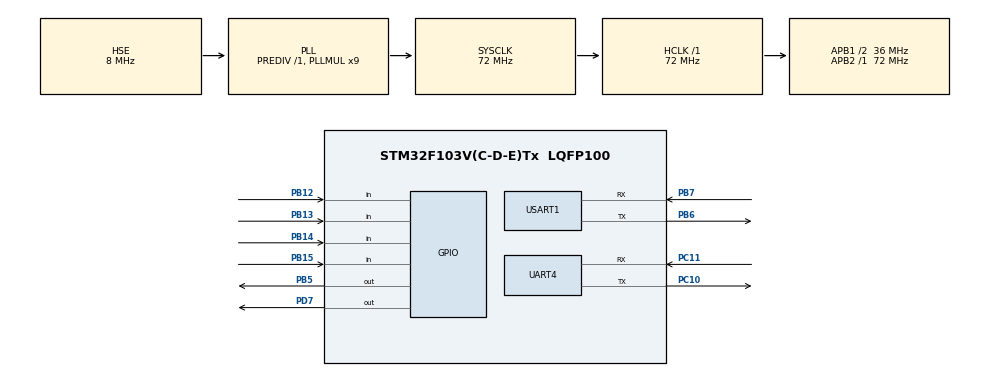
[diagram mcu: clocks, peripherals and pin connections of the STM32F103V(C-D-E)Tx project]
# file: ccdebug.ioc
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Dma.Request0=USART1_RX
Dma.Request1=UART4_RX
Dma.UART4_RX.1.Direction=DMA_PERIPH_TO_MEMORY
Dma.UART4_RX.1.Instance=DMA2_Channel3
Dma.UART4_RX.1.MemDataAlignment=DMA_MDATAALIGN_BYTE
Dma.UART4_RX.1.MemInc=DMA_MINC_ENABLE
Dma.UART4_RX.1.Mode=DMA_NORMAL
Dma.UART4_RX.1.PeriphDataAlignment=DMA_PDATAALIGN_BYTE
Dma.UART4_RX.1.PeriphInc=DMA_PINC_DISABLE
Dma.UART4_RX.1.Priority=DMA_PRIORITY_LOW
Dma.USART1_RX.0.Direction=DMA_PERIPH_TO_MEMORY
Dma.USART1_RX.0.Instance=DMA1_Channel5
Dma.USART1_RX.0.MemDataAlignment=DMA_MDATAALIGN_BYTE
Dma.USART1_RX.0.MemInc=DMA_MINC_ENABLE
Dma.USART1_RX.0.Mode=DMA_NORMAL
Dma.USART1_RX.0.PeriphDataAlignment=DMA_PDATAALIGN_BYTE
Dma.USART1_RX.0.PeriphInc=DMA_PINC_DISABLE
Dma.USART1_RX.0.Priority=DMA_PRIORITY_LOW
Mcu.Family=STM32F1
Mcu.Name=STM32F103V(C-D-E)Tx
Mcu.Package=LQFP100
NVIC.DMA1_Channel5_IRQn=true\:2\:1\:true\:false\:true\:false
NVIC.DMA2_Channel3_IRQn=true\:2\:2\:true\:false\:true\:false
NVIC.PriorityGroup=NVIC_PRIORITYGROUP_2
NVIC.RCC_IRQn=true\:0\:0\:false\:false\:true\:true
NVIC.TIM6_IRQn=true\:1\:2\:true\:false\:true\:true
NVIC.TIM7_IRQn=true\:1\:1\:true\:false\:true\:true
NVIC.UART4_IRQn=true\:3\:3\:true\:false\:true\:true
NVIC.USART1_IRQn=true\:3\:2\:true\:false\:true\:true
OSC_IN.Mode=HSE-External-Oscillator
OSC_IN.Signal=RCC_OSC_IN
OSC_OUT.Mode=HSE-External-Oscillator
OSC_OUT.Signal=RCC_OSC_OUT
PB12.Signal=GPIO_Input
PB13.Signal=GPIO_Input
PB14.Signal=GPIO_Input
PB15.Signal=GPIO_Input
PB5.Signal=GPIO_Output
PB6.Mode=Asynchronous
PB6.Signal=USART1_TX
PB7.Mode=Asynchronous
PB7.Signal=USART1_RX
PC10.Mode=Asynchronous
PC10.Signal=UART4_TX
PC11.Mode=Asynchronous
PC11.Signal=UART4_RX
PD7.Signal=GPIO_Output
ProjectManager.HeapSize=0x200
ProjectManager.StackSize=0x400
ProjectManager.TargetToolchain=EWARM V8
RCC.AHBFreq_Value=72000000
RCC.APB1CLKDivider=RCC_HCLK_DIV2
RCC.APB1Freq_Value=36000000
RCC.APB1TimFreq_Value=72000000
RCC.APB2Freq_Value=72000000
RCC.APB2TimFreq_Value=72000000
RCC.HCLKFreq_Value=72000000
RCC.PLLMUL=RCC_PLL_MUL9
RCC.PLLSourceVirtual=RCC_PLLSOURCE_HSE
RCC.SYSCLKFreq_VALUE=72000000
RCC.SYSCLKSource=RCC_SYSCLKSOURCE_PLLCLK
RCC.USBFreq_Value=72000000
UART4.Parity=PARITY_EVEN
UART4.VirtualMode=Asynchronous
UART4.WordLength=WORDLENGTH_9B
USART1.Parity=PARITY_EVEN
USART1.VirtualMode=VM_ASYNC
USART1.WordLength=WORDLENGTH_9B
VP_SYS_VS_ND.Mode=No_Debug
VP_TIM6_VS_ClockSourceINT.Mode=Enable_Timer
VP_TIM7_VS_ClockSourceINT.Mode=Enable_Timer
board=custom

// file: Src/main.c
/* USER CODE BEGIN Header */
/**
  ******************************************************************************
  * @file           : main.c
  * @brief          : Main program body
  ******************************************************************************
  ** This notice applies to any and all portions of this file
  * that are not between comment pairs USER CODE BEGIN and
  * USER CODE END. Other portions of this file, whether
  * inserted by the user or by software development tools
  * are owned by their respective copyright owners.
  *
  * COPYRIGHT(c) 2018 STMicroelectronics
  *
  * Redistribution and use in source and binary forms, with or without modification,
  * are permitted provided that the following conditions are met:
  *   1. Redistributions of source code must retain the above copyright notice,
  *      this list of conditions and the following disclaimer.
  *   2. Redistributions in binary form must reproduce the above copyright notice,
  *      this list of conditions and the following disclaimer in the documentation
  *      and/or other materials provided with the distribution.
  *   3. Neither the name of STMicroelectronics nor the names of its contributors
  *      may be used to endorse or promote products derived from this software
  *      without specific prior written permission.
  *
  * THIS SOFTWARE IS PROVIDED BY THE COPYRIGHT HOLDERS AND CONTRIBUTORS "AS IS"
  * AND ANY EXPRESS OR IMPLIED WARRANTIES, INCLUDING, BUT NOT LIMITED TO, THE
  * IMPLIED WARRANTIES OF MERCHANTABILITY AND FITNESS FOR A PARTICULAR PURPOSE ARE
  * DISCLAIMED. IN NO EVENT SHALL THE COPYRIGHT HOLDER OR CONTRIBUTORS BE LIABLE
  * FOR ANY DIRECT, INDIRECT, INCIDENTAL, SPECIAL, EXEMPLARY, OR CONSEQUENTIAL
  * DAMAGES (INCLUDING, BUT NOT LIMITED TO, PROCUREMENT OF SUBSTITUTE GOODS OR
  * SERVICES; LOSS OF USE, DATA, OR PROFITS; OR BUSINESS INTERRUPTION) HOWEVER
  * CAUSED AND ON ANY THEORY OF LIABILITY, WHETHER IN CONTRACT, STRICT LIABILITY,
  * OR TORT (INCLUDING NEGLIGENCE OR OTHERWISE) ARISING IN ANY WAY OUT OF THE USE
  * OF THIS SOFTWARE, EVEN IF ADVISED OF THE POSSIBILITY OF SUCH DAMAGE.
  *
  ******************************************************************************
  */
/* USER CODE END Header */

#include "main.h"
#include "module.h"

TIM_HandleTypeDef htim6;
TIM_HandleTypeDef htim7;

UART_HandleTypeDef huart4;
UART_HandleTypeDef huart1;
DMA_HandleTypeDef hdma_uart4_rx;
DMA_HandleTypeDef hdma_usart1_rx;

void SystemClock_Config(void);
static void MX_GPIO_Init(void);
static void MX_DMA_Init(void);
static void MX_TIM6_Init(void);
static void MX_TIM7_Init(void);
static void MX_UART4_Init(void);
static void MX_USART1_UART_Init(void);
uint8_t led_flag;

int main(void)
{

  /* MCU Configuration--------------------------------------------------------*/

  /* Reset of all peripherals, Initializes the Flash interface and the Systick. */
  HAL_Init();

  /* Configure the system clock */
  SystemClock_Config();

  /* Initialize all configured peripherals */
  MX_GPIO_Init();
  MX_DMA_Init();
  MX_TIM6_Init();
  MX_TIM7_Init();
  MX_UART4_Init();
  MX_USART1_UART_Init();
  /* USER CODE BEGIN 2 */
  RS_485_RX();

  init();
  /* USER CODE END 2 */
  led_flag=1;
  /* Infinite loop */
  while (1)
  {
     process_cmd_tx_rx();
  }
}
void HAL_SYSTICK_Callback()
{
  uint32_t tickStart = HAL_GetTick();
  if(led_flag==1)
  {

    if(tickStart%200==0)
    HAL_GPIO_TogglePin(LED1_PORT,LED1_PIN);
  }
  else if(led_flag==2)
  {
   if(tickStart%1000==0)
    HAL_GPIO_TogglePin(LED1_PORT,LED1_PIN);
  }
   else if(led_flag==3)
  {
     if(tickStart%1000==0)
    HAL_GPIO_TogglePin(LED1_PORT,LED1_PIN);
  }

 }
void SystemClock_Config(void)
{
  RCC_OscInitTypeDef RCC_OscInitStruct = {0};
  RCC_ClkInitTypeDef RCC_ClkInitStruct = {0};

  /**Initializes the CPU, AHB and APB busses clocks
  */
  RCC_OscInitStruct.OscillatorType = RCC_OSCILLATORTYPE_HSE;
  RCC_OscInitStruct.HSEState = RCC_HSE_ON;
  RCC_OscInitStruct.HSEPredivValue = RCC_HSE_PREDIV_DIV1;
  RCC_OscInitStruct.HSIState = RCC_HSI_ON;
  RCC_OscInitStruct.PLL.PLLState = RCC_PLL_ON;
  RCC_OscInitStruct.PLL.PLLSource = RCC_PLLSOURCE_HSE;
  RCC_OscInitStruct.PLL.PLLMUL = RCC_PLL_MUL9;
  if (HAL_RCC_OscConfig(&RCC_OscInitStruct) != HAL_OK)
  {
    Error_Handler();
  }
  /**Initializes the CPU, AHB and APB busses clocks
  */
  RCC_ClkInitStruct.ClockType = RCC_CLOCKTYPE_HCLK|RCC_CLOCKTYPE_SYSCLK
                              |RCC_CLOCKTYPE_PCLK1|RCC_CLOCKTYPE_PCLK2;
  RCC_ClkInitStruct.SYSCLKSource = RCC_SYSCLKSOURCE_PLLCLK;
  RCC_ClkInitStruct.AHBCLKDivider = RCC_SYSCLK_DIV1;
  RCC_ClkInitStruct.APB1CLKDivider = RCC_HCLK_DIV2;
  RCC_ClkInitStruct.APB2CLKDivider = RCC_HCLK_DIV1;

  if (HAL_RCC_ClockConfig(&RCC_ClkInitStruct, FLASH_LATENCY_2) != HAL_OK)
  {
    Error_Handler();
  }
}

static void MX_TIM6_Init(void)
{

  TIM_MasterConfigTypeDef sMasterConfig = {0};

  htim6.Instance = TIM6;
  htim6.Init.Prescaler = 719;
  htim6.Init.CounterMode = TIM_COUNTERMODE_UP;
  htim6.Init.Period = 4999;
  htim6.Init.AutoReloadPreload = TIM_AUTORELOAD_PRELOAD_DISABLE;
  if (HAL_TIM_Base_Init(&htim6) != HAL_OK)
  {
    Error_Handler();
  }
  sMasterConfig.MasterOutputTrigger = TIM_TRGO_RESET;
  sMasterConfig.MasterSlaveMode = TIM_MASTERSLAVEMODE_DISABLE;
  if (HAL_TIMEx_MasterConfigSynchronization(&htim6, &sMasterConfig) != HAL_OK)
  {
    Error_Handler();
  }

}

static void MX_TIM7_Init(void)
{

  TIM_MasterConfigTypeDef sMasterConfig = {0};

  htim7.Instance = TIM7;
  htim7.Init.Prescaler = 0;
  htim7.Init.CounterMode = TIM_COUNTERMODE_UP;
  htim7.Init.Period = 0;
  htim7.Init.AutoReloadPreload = TIM_AUTORELOAD_PRELOAD_DISABLE;
  if (HAL_TIM_Base_Init(&htim7) != HAL_OK)
  {
    Error_Handler();
  }
  sMasterConfig.MasterOutputTrigger = TIM_TRGO_RESET;
  sMasterConfig.MasterSlaveMode = TIM_MASTERSLAVEMODE_DISABLE;
  if (HAL_TIMEx_MasterConfigSynchronization(&htim7, &sMasterConfig) != HAL_OK)
  {
    Error_Handler();
  }

}

static void MX_UART4_Init(void)
{

  huart4.Instance = UART4;
  huart4.Init.BaudRate = 9600;
  huart4.Init.WordLength = UART_WORDLENGTH_9B;
  huart4.Init.StopBits = UART_STOPBITS_1;
  huart4.Init.Parity = UART_PARITY_EVEN;
  huart4.Init.Mode = UART_MODE_TX_RX;
  huart4.Init.HwFlowCtl = UART_HWCONTROL_NONE;
  huart4.Init.OverSampling = UART_OVERSAMPLING_16;
  if (HAL_UART_Init(&huart4) != HAL_OK)
  {
    Error_Handler();
  }

}

static void MX_USART1_UART_Init(void)
{

  huart1.Instance = USART1;
  huart1.Init.BaudRate = 2400;
  huart1.Init.WordLength = UART_WORDLENGTH_9B;
  huart1.Init.StopBits = UART_STOPBITS_1;
  huart1.Init.Parity = UART_PARITY_EVEN;
  huart1.Init.Mode = UART_MODE_TX_RX;
  huart1.Init.HwFlowCtl = UART_HWCONTROL_NONE;
  huart1.Init.OverSampling = UART_OVERSAMPLING_16;
  if (HAL_UART_Init(&huart1) != HAL_OK)
  {
    Error_Handler();
  }

}

static void MX_DMA_Init(void)
{
  /* DMA controller clock enable */
  __HAL_RCC_DMA1_CLK_ENABLE();
  __HAL_RCC_DMA2_CLK_ENABLE();

  /* DMA interrupt init */
  /* DMA1_Channel5_IRQn interrupt configuration */
  HAL_NVIC_SetPriority(DMA1_Channel5_IRQn, 2, 1);
  HAL_NVIC_EnableIRQ(DMA1_Channel5_IRQn);
  /* DMA2_Channel3_IRQn interrupt configuration */
  HAL_NVIC_SetPriority(DMA2_Channel3_IRQn, 2, 2);
  HAL_NVIC_EnableIRQ(DMA2_Channel3_IRQn);

}

static void MX_GPIO_Init(void)
{
  GPIO_InitTypeDef GPIO_InitStruct = {0};

  /* GPIO Ports Clock Enable */
  __HAL_RCC_GPIOB_CLK_ENABLE();
  __HAL_RCC_GPIOC_CLK_ENABLE();
  __HAL_RCC_GPIOD_CLK_ENABLE();

  /*Configure GPIO pin Output Level */
  HAL_GPIO_WritePin(GPIOD, GPIO_PIN_7, GPIO_PIN_RESET);

  /*Configure GPIO pin Output Level */
  HAL_GPIO_WritePin(GPIOB, GPIO_PIN_5, GPIO_PIN_RESET);

  /*Configure GPIO pins : PB12 PB13 PB14 PB15 */
  GPIO_InitStruct.Pin = GPIO_PIN_12|GPIO_PIN_13|GPIO_PIN_14|GPIO_PIN_15;
  GPIO_InitStruct.Mode = GPIO_MODE_INPUT;
  GPIO_InitStruct.Pull = GPIO_NOPULL;
  HAL_GPIO_Init(GPIOB, &GPIO_InitStruct);

  /*Configure GPIO pin : PD7 */
  GPIO_InitStruct.Pin = GPIO_PIN_7;
  GPIO_InitStruct.Mode = GPIO_MODE_OUTPUT_PP;
  GPIO_InitStruct.Pull = GPIO_NOPULL;
  GPIO_InitStruct.Speed = GPIO_SPEED_FREQ_LOW;
  HAL_GPIO_Init(GPIOD, &GPIO_InitStruct);

  /*Configure GPIO pin : PB5 */
  GPIO_InitStruct.Pin = GPIO_PIN_1|GPIO_PIN_5;
  GPIO_InitStruct.Mode = GPIO_MODE_OUTPUT_PP;
  GPIO_InitStruct.Pull = GPIO_NOPULL;
  GPIO_InitStruct.Speed = GPIO_SPEED_FREQ_LOW;
  HAL_GPIO_Init(GPIOB, &GPIO_InitStruct);

}

void Error_Handler(void)
{
}

/************************ (C) COPYRIGHT STMicroelectronics *****END OF FILE****/
